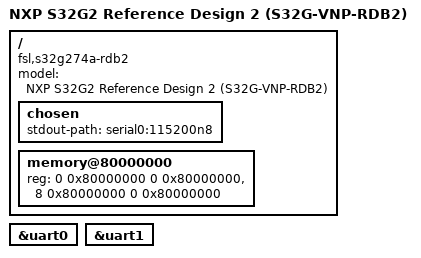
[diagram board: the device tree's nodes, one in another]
// SPDX-License-Identifier: GPL-2.0-or-later OR MIT
/*
 * Copyright (c) 2021 SUSE LLC
 * Copyright 2019-2020 NXP
 */

/dts-v1/;

#include "s32g2.dtsi"

/ {
	model = "NXP S32G2 Reference Design 2 (S32G-VNP-RDB2)";
	compatible = "fsl,s32g274a-rdb2", "fsl,s32g2";

	chosen {
		stdout-path = "serial0:115200n8";
	};

	memory@80000000 {
		device_type = "memory";
		/* 4GB RAM */
		reg = <0 0x80000000 0 0x80000000>,
		      <8 0x80000000 0 0x80000000>;
	};
};

&uart0 {
	status = "okay";
};

&uart1 {
	status = "okay";
};
